# nrf7140_secure register map
Vendor: Nordic Semiconductor; Series: nRF71; File version: 1
CPU: CM33 r0p4, little endian, MPU, no FPU, 3 interrupt priority bits, 480 interrupts, 8 SAU regions
Registers are 32-bit, read-write, reset 0x0 unless marked. A register's access mark holds for its fields unless they carry their own. Offsets are from the block's base; [hi:lo] are bit positions; lines under a group give offsets from that group; {n}, {i} and the like mark numbered series.

## MEMCONF200_NS — Memory configuration 0
Base 0xBF014000
Same registers: MEMCONF_NS 0x41012000, GLOBAL_MEMCONF310_NS 0x49011000, MEMCONF_S 0x51012000
{0x500+0x10*i} POWER[{i}] (i=0..1) group — Unspecified
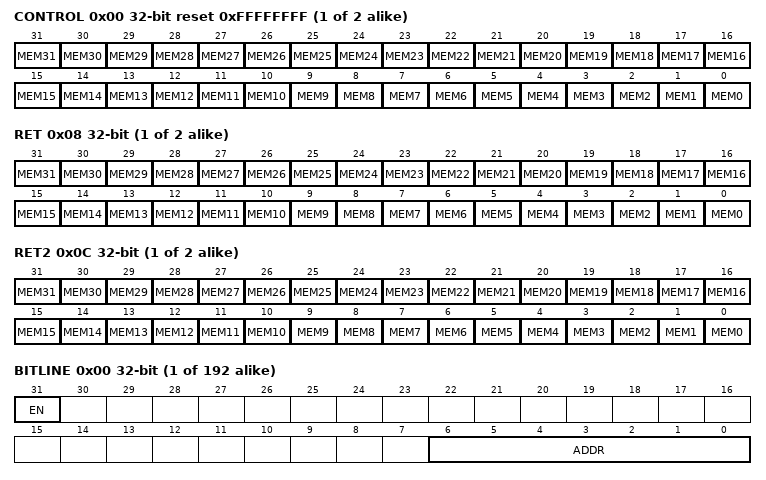
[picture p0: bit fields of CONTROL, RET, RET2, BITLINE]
  0x00 CONTROL reset 0xFFFFFFFF — Description cluster: Control memory block power.
    [all] fields
      0=Off (Power down); 1=On (Power up)
    [n] MEM{n} (n=0..31) — Keep the memory block MEM[{n}] on or off when in System ON mode.
  0x08 RET — Description cluster: RAM retention for RAM [n].
    [all] fields
      0=Off (Retention off); 1=On (Retention on)
    [n] MEM{n} (n=0..31) — Keep the RAM block MEM[{n}] retained when the parent power domain of the RAM is off.
  0x0C RET2 — Description cluster: RAM retention for the second bank in the RAM block
    [all] fields
      0=Off (Retention off); 1=On (Retention on)
    [n] MEM{n} (n=0..31) — Keep the second bank in RAM block MEM[{n}] retained when parent power domain of the RAM is off.
{0x600+4i} REPAIR[{i}] (i=0..191) group — Unspecified
  0x00 BITLINE — Description cluster: Repair configuration for RAM blocks.
    [31] EN — Enable bitline repair
      0=Disabled (Repair disabled.); 1=Enabled (Repair enabled.)
    [6:0] ADDR — Repair address of the bitline
{0x900+4i} BLOCKTYPE[{i}] (i=0..63) group — Unspecified
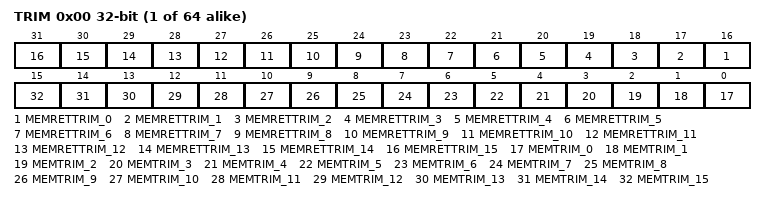
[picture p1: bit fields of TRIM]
  0x00 TRIM — Description cluster: Trim configuration for the memory block types.
    [n+16] MEMRETTRIM_{n} (n=0..15) — Trimming for retention mode for decreased leakage. Must be kept active in RAM retention mode.
    [n] MEMTRIM_{n} (n=0..15) — Read/write margin trim.

## GLOBAL_TSGEN_NS — Timestamp generator
Base 0xBF041000
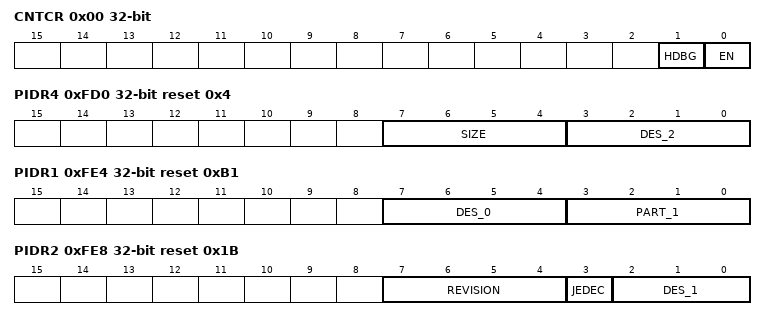
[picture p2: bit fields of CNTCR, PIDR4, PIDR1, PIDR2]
0x00 CNTCR — Counter Control Register
  [1] HDBG — Halt on Debug
    0=Disabled (Do not halt on debug, HLTDBG signal into the counter has no effect.); 1=Enabled (Halt on debug, when HLTDBG is driven HIGH, the count value is held static.)
  [0] EN — Counter enable
    0=Disabled (Unspecified); 1=Enabled (Unspecified)
0x04 CNTSR ro — Counter Status Register
  [1] DBGH — Debug halted
0x08 CNTCVL — Current Counter Value Lower register
  [31:0] CNTCVL_L_32 — Current value of Counter, lower 32 bits
0x0C CNTCVU — Current Counter Value Upper register
  [31:0] CNTCVU_U_32 — Current value of Counter, upper 32 bits
0x20 CNTFID0 — Base Frequency ID
  [31:0] FREQ — Frequency in number of ticks per second (up to 4 GHz)
0xFD0 PIDR4 ro reset 0x4 — Peripheral ID4 Register
  [7:4] SIZE — This is a 4-bit value that indicates the total contiguous size of the memory window used by this component in powers of 2 from the standard 4KB. If a component only requires the standard 4KB, this must read as 0x0, 4KB only. For 8KB set to 0x1, for 16KB set to 0x2, for 32KB set to 0x3, and so on.
  [3:0] DES_2 — JEDEC continuation code indicating the designer of the component, together with the identity code.
0xFE0 PIDR0 ro reset 0x1 — Peripheral ID0 Register
  [7:0] PART_0 — Bits [7:0] of the component part number. This is selected by the designer of the component.
0xFE4 PIDR1 ro reset 0xB1 — Peripheral ID1 Register
  [7:4] DES_0 — Bits [3:0] of the JEDEC identity code indicating the designer of the component, together with the continuation code.
  [3:0] PART_1 — Bits [11:8] of the component part number. This is selected by the designer of the component.
0xFE8 PIDR2 ro reset 0x1B — Peripheral ID2 Register
  [7:4] REVISION — The Revision field is an incremental value starting at 0x0 for the first design of this component. This only increases by 1 for both major and minor revisions and is used as a look-up to establish the exact major and minor revision.
  [3] JEDEC — Always set. Indicates that a JEDEC assigned value is used.
  [2:0] DES_1 — Bits [6:4] of the JEDEC identity code indicating the designer of the component, together with the continuation code.
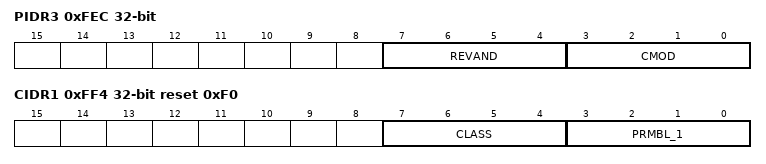
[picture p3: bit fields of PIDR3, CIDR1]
0xFEC PIDR3 ro — Peripheral ID3 Register
  [7:4] REVAND — This field indicates minor errata fixes specific to this design, for example metal fixes after implementation. In most cases this field is zero. It is recommended that component designers ensure this field can be changed by a metal fix if required, for example by driving it from registers that reset to zero.
  [3:0] CMOD — Where the component is reusable IP, this value indicates if the customer has modified the behavior of the component. In most cases this field is zero.
0xFF0 CIDR0 ro reset 0xD — Component ID0 Register
  [7:0] PRMBL_0 — Contains bits[7:0] of the component identification code.
0xFF4 CIDR1 ro reset 0xF0 — Component ID1 Register
  [7:4] CLASS — Class of the component, for example, ROM table or CoreSight component.
  [3:0] PRMBL_1 — Contains bits[11:8] of the component identification code.
0xFF8 CIDR2 ro reset 0x5 — Component ID2 Register
  [7:0] PRMBL_2 — Contains bits[23:16] of the component identification code.
0xFFC CIDR3 ro reset 0xB1 — Component ID3 Register
  [7:0] PRMBL_3 — Contains bits[31:24] of the component identification code.

## Notices in the file
Copyright (c) 2010 - 2024, Nordic Semiconductor ASA
All rights reserved.
Redistribution and use in source and binary forms, with or without modification,
are permitted provided that the following conditions are met:
1. Redistributions of source code must retain the above copyright notice, this
list of conditions and the following disclaimer.
2. Redistributions in binary form, except as embedded into a Nordic
Semiconductor ASA integrated circuit in a product or a software update for
such product, must reproduce the above copyright notice, this list of
conditions and the following disclaimer in the documentation and/or other
materials provided with the distribution.
3. Neither the name of Nordic Semiconductor ASA nor the names of its
contributors may be used to endorse or promote products derived from this
software without specific prior written permission.
4. This software, with or without modification, must only be used with a
Nordic Semiconductor ASA integrated circuit.
5. Any software provided in binary form under this license must not be reverse
engineered, decompiled, modified and/or disassembled.
THIS SOFTWARE IS PROVIDED BY NORDIC SEMICONDUCTOR ASA "AS IS" AND ANY EXPRESS
OR IMPLIED WARRANTIES, INCLUDING, BUT NOT LIMITED TO, THE IMPLIED WARRANTIES
OF MERCHANTABILITY, NONINFRINGEMENT, AND FITNESS FOR A PARTICULAR PURPOSE ARE
DISCLAIMED. IN NO EVENT SHALL NORDIC SEMICONDUCTOR ASA OR CONTRIBUTORS BE
LIABLE FOR ANY DIRECT, INDIRECT, INCIDENTAL, SPECIAL, EXEMPLARY, OR
CONSEQUENTIAL DAMAGES (INCLUDING, BUT NOT LIMITED TO, PROCUREMENT OF SUBSTITUTE
GOODS OR SERVICES; LOSS OF USE, DATA, OR PROFITS; OR BUSINESS INTERRUPTION)
HOWEVER CAUSED AND ON ANY THEORY OF LIABILITY, WHETHER IN CONTRACT, STRICT
LIABILITY, OR TORT (INCLUDING NEGLIGENCE OR OTHERWISE) ARISING IN ANY WAY OUT
OF THE USE OF THIS SOFTWARE, EVEN IF ADVISED OF THE POSSIBILITY OF SUCH DAMAGE.
